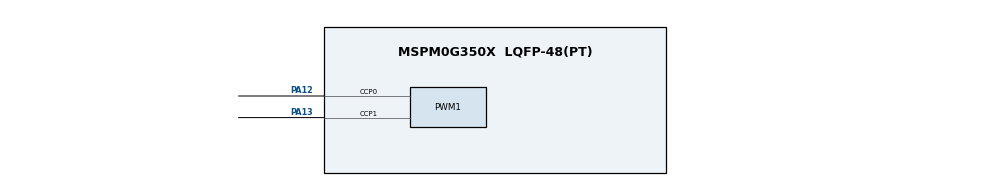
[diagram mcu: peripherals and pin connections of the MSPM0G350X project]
/**
 *
 * @cliArgs --device "MSPM0G350X" --part "Default" --package "LQFP-48(PT)" --product "mspm0_sdk@2.11.00.07"
 * @versions {"tool":"1.28.0+4712"}
 */

/**
 * Import the modules used in this configuration.
 */
const GPIO          = scripting.addModule("/ti/driverlib/GPIO", {}, false);
const GPIO1         = GPIO.addInstance();
const PWM           = scripting.addModule("/ti/driverlib/PWM", {}, false);
const PWM1          = PWM.addInstance();
const ProjectConfig = scripting.addModule("/ti/project_config/ProjectConfig");

/**
 * Write custom configuration values to the imported modules.
 */
GPIO1.$name                                 = "USER";
GPIO1.associatedPins[0].assignedPin         = "14";
GPIO1.associatedPins[0].assignedPort        = "PORTA";
GPIO1.associatedPins[0].assignedPortSegment = "Lower";
GPIO1.associatedPins[0].$name               = "LEDboard";

const Board = scripting.addModule("/ti/driverlib/Board", {}, false);

PWM1.timerCount                         = 32000;
PWM1.$name                              = "LED_PWM";
PWM1.peripheral.$assign                 = "TIMG0";
PWM1.peripheral.ccp0Pin.$assign         = "PA12";
PWM1.peripheral.ccp1Pin.$assign         = "PA13";
PWM1.PWM_CHANNEL_0.$name                = "ti_driverlib_pwm_PWMTimerCC0";
PWM1.PWM_CHANNEL_1.$name                = "ti_driverlib_pwm_PWMTimerCC1";
PWM1.ccp0PinConfig.$name                = "ti_driverlib_gpio_GPIOPinGeneric0";
PWM1.ccp0PinConfig.direction            = scripting.forceWrite("OUTPUT");
PWM1.ccp0PinConfig.hideOutputInversion  = scripting.forceWrite(false);
PWM1.ccp0PinConfig.onlyInternalResistor = scripting.forceWrite(false);
PWM1.ccp0PinConfig.passedPeripheralType = scripting.forceWrite("Digital");
PWM1.ccp1PinConfig.$name                = "ti_driverlib_gpio_GPIOPinGeneric1";
PWM1.ccp1PinConfig.direction            = scripting.forceWrite("OUTPUT");
PWM1.ccp1PinConfig.hideOutputInversion  = scripting.forceWrite(false);
PWM1.ccp1PinConfig.onlyInternalResistor = scripting.forceWrite(false);
PWM1.ccp1PinConfig.passedPeripheralType = scripting.forceWrite("Digital");

const SYSCTL = scripting.addModule("/ti/driverlib/SYSCTL", {}, false);

ProjectConfig.compiler = "gcc";

/**
 * Pinmux solution for unlocked pins/peripherals. This ensures that minor changes to the automatic solver in a future
 * version of the tool will not impact the pinmux you originally saw.  These lines can be completely deleted in order to
 * re-solve from scratch.
 */
GPIO1.associatedPins[0].pin.$suggestSolution = "PA14";
Board.peripheral.$suggestSolution            = "DEBUGSS";
Board.peripheral.swclkPin.$suggestSolution   = "PA20";
Board.peripheral.swdioPin.$suggestSolution   = "PA19";
SYSCTL.peripheral.$suggestSolution           = "SYSCTL";
